# STM32L072xx register map
File version: 1.0
Registers are 32-bit, read-write, reset 0x0 unless marked. A register's access mark holds for its fields unless they carry their own. Offsets are from the block's base; [hi:lo] are bit positions; lines under a group give offsets from that group.

## ADC1 — Analog to Digital Converter
Base 0x40012400
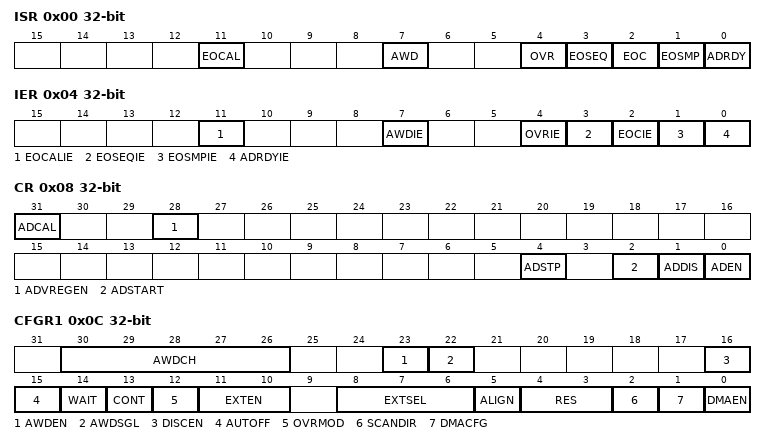
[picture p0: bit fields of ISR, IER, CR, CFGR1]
0x00 ISR — ADC Interrupt and Status register
  [11] EOCAL — End of calibration flag
  [7] AWD — Analog watchdog flag
  [4] OVR — Overrun flag
  [3] EOSEQ — End of Sequence flag
  [2] EOC — End of Conversion
  [1] EOSMP — End of sampling flag
  [0] ADRDY — ADC Ready
0x04 IER — ADC Interrupt Enable register
  [11] EOCALIE — Enf Of Calibration interrupt enable
  [7] AWDIE — Analog Watchdog interrupt enable
  [4] OVRIE — Overrun interrupt enable
  [3] EOSEQIE — End of Sequence of conversion interrupt enable
  [2] EOCIE — End of Conversion interrupt enable
  [1] EOSMPIE — End of sampling interrupt enable
  [0] ADRDYIE — ADC Ready interrupt enable
0x08 CR — ADC Control register
  [31] ADCAL — ADC calibration
  [28] ADVREGEN — ADC Voltage Regulator Enable
  [4] ADSTP — ADC stop of conversion command
  [2] ADSTART — ADC start of conversion
  [1] ADDIS — ADC disable command
  [0] ADEN — ADC enable control
0x0C CFGR1 — ADC Configuration register 1
  [30:26] AWDCH — AWDCH[4:0] bits (Analog watchdog channel select bits)
  [23] AWDEN — Analog watchdog enable on regular channels
  [22] AWDSGL — Enable the watchdog on a single channel or on all channels
  [16] DISCEN — Discontinuous mode on regular channels
    0=DISABLE (ADC group regular sequencer discontinuous mode disable); 1=DISCONT_1RANK (ADC group regular sequencer discontinuous mode enable with sequence interruption every rank)
  [15] AUTOFF — ADC auto power off
  [14] WAIT — ADC wait conversion mode
  [13] CONT — Continuous Conversion
    0=SINGLE (ADC conversions are performed in single mode: one conversion per trigger); 1=CONTINUOUS (ADC conversions are performed in continuous mode: after the first trigger, following conversions launched successively automatically)
  [12] OVRMOD — Overrun mode
    0=PRESERVED (ADC group regular behavior in case of overrun: data preserved); 1=OVERWRITTEN (ADC group regular behavior in case of overrun: data overwritten)
  [11:10] EXTEN — EXTEN[1:0] bits (External Trigger Conversion mode for regular channels)
    1=RISING (ADC group regular conversion trigger polarity set to rising edge); 2=FALLING (ADC group regular conversion trigger polarity set to falling edge); 3=RISINGFALLING (ADC group regular conversion trigger polarity set to both rising and falling edges)
  [8:6] EXTSEL — EXTSEL[2:0] bits (External Event Select for regular group)
  [5] ALIGN — Data Alignment
    0=RIGHT (ADC conversion data alignment: right aligned (alignment on data register LSB bit 0)); 1=LEFT (ADC conversion data alignment: left aligned (alignment on data register MSB bit 15))
  [4:3] RES — RES[1:0] bits (Resolution)
    0=RESOLUTION_12B (ADC resolution 12 bits); 1=RESOLUTION_10B (ADC resolution 10 bits); 2=RESOLUTION_8B (ADC resolution 8 bits); 3=RESOLUTION_6B (ADC resolution 6 bits)
  [2] SCANDIR — Sequence scan direction
    0=FORWARD (ADC group regular sequencer scan direction forward: from lowest channel number to highest channel number (scan of all ranks, ADC conversion of ranks with channels enabled in sequencer). On some other STM32 families, this setting is not available and the default scan direction is forward.); 1=BACKWARD (ADC group regular sequencer scan direction backward: from highest channel number to lowest channel number (scan of all ranks, ADC conversion of ranks with channels enabled in sequencer))
  [1] DMACFG — Direct memory access configuration
  [0] DMAEN — Direct memory access enable
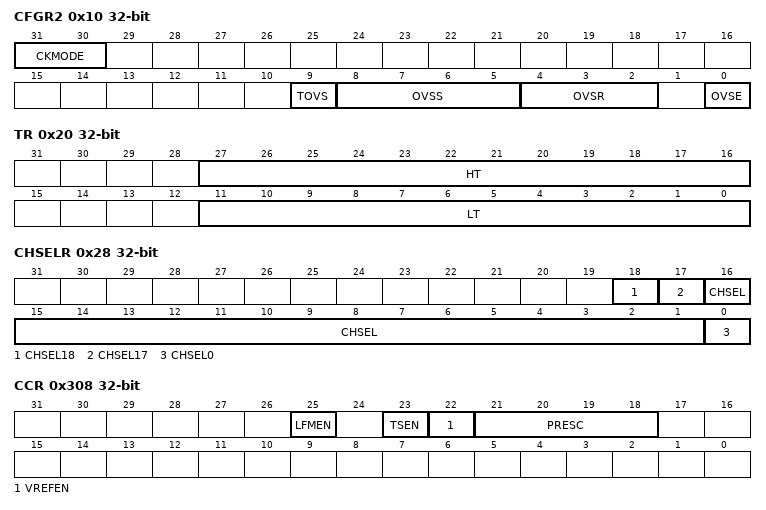
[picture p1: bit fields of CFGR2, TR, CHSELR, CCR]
0x10 CFGR2 — ADC Configuration register 2
  [31:30] CKMODE — CKMODE [1:0] bits (ADC clock mode)
    2=SYNC_PCLK_DIV4 (ADC synchronous clock derived from AHB clock divided by 4); 1=SYNC_PCLK_DIV2 (ADC synchronous clock derived from AHB clock divided by 2); 3=SYNC_PCLK_DIV1 (ADC synchronous clock derived from AHB clock not divided); 0=ASYNC (ADC asynchronous clock. Asynchronous clock prescaler can be configured using function @ref LL_ADC_SetCommonClock().)
  [9] TOVS — Triggered Oversampling
    0=CONT (ADC oversampling discontinuous mode: continuous mode (all conversions of oversampling ratio are done from 1 trigger)); 1=DISCONT (ADC oversampling discontinuous mode: discontinuous mode (each conversion of oversampling ratio needs a trigger))
  [8:5] OVSS — OVSS [3:0] bits (Oversampling shift)
    0=NONE (ADC oversampling no shift (sum of the ADC conversions data is not divided to result as the ADC oversampling conversion data)); 1=RIGHT_1 (ADC oversampling shift of 1 (sum of the ADC conversions data is divided by 2 to result as the ADC oversampling conversion data)); 2=RIGHT_2 (ADC oversampling shift of 2 (sum of the ADC conversions data is divided by 4 to result as the ADC oversampling conversion data)); 3=RIGHT_3 (ADC oversampling shift of 3 (sum of the ADC conversions data is divided by 8 to result as the ADC oversampling conversion data)); 4=RIGHT_4 (ADC oversampling shift of 4 (sum of the ADC conversions data is divided by 16 to result as the ADC oversampling conversion data)); 5=RIGHT_5 (ADC oversampling shift of 5 (sum of the ADC conversions data is divided by 32 to result as the ADC oversampling conversion data)); 6=RIGHT_6 (ADC oversampling shift of 6 (sum of the ADC conversions data is divided by 64 to result as the ADC oversampling conversion data)); 7=RIGHT_7 (ADC oversampling shift of 7 (sum of the ADC conversions data is divided by 128 to result as the ADC oversampling conversion data)); 8=RIGHT_8 (ADC oversampling shift of 8 (sum of the ADC conversions data is divided by 256 to result as the ADC oversampling conversion data))
  [4:2] OVSR — OVSR [2:0] bits (Oversampling ratio)
    0=RATIO_2 (ADC oversampling ratio of 2 (2 ADC conversions are performed, sum of these conversions data is computed to result as the ADC oversampling conversion data (before potential shift)); 1=RATIO_4 (ADC oversampling ratio of 4 (4 ADC conversions are performed, sum of these conversions data is computed to result as the ADC oversampling conversion data (before potential shift)); 2=RATIO_8 (ADC oversampling ratio of 8 (8 ADC conversions are performed, sum of these conversions data is computed to result as the ADC oversampling conversion data (before potential shift)); 3=RATIO_16 (ADC oversampling ratio of 16 (16 ADC conversions are performed, sum of these conversions data is computed to result as the ADC oversampling conversion data (before potential shift)); 4=RATIO_32 (ADC oversampling ratio of 32 (32 ADC conversions are performed, sum of these conversions data is computed to result as the ADC oversampling conversion data (before potential shift)); 5=RATIO_64 (ADC oversampling ratio of 64 (64 ADC conversions are performed, sum of these conversions data is computed to result as the ADC oversampling conversion data (before potential shift)); 6=RATIO_128 (ADC oversampling ratio of 128 (128 ADC conversions are performed, sum of these conversions data is computed to result as the ADC oversampling conversion data (before potential shift)); 7=RATIO_256 (ADC oversampling ratio of 256 (256 ADC conversions are performed, sum of these conversions data is computed to result as the ADC oversampling conversion data (before potential shift))
  [0] OVSE — Oversampler Enable
    0=DISABLE (ADC oversampling disabled.); 1=GRP_REGULAR_CONTINUED (ADC oversampling on conversions of ADC group regular. Literal suffix "continued" is kept for compatibility with other STM32 devices featuring ADC group injected, in this case other oversampling scope parameters are available.)
0x14 SMPR — ADC Sampling time register
  [2:0] SMP — SMPR[2:0] bits (Sampling time selection)
    0=SAMPLINGTIME_1CYCLE_5 (Sampling time 1.5 ADC clock cycle); 1=SAMPLINGTIME_3CYCLES_5 (Sampling time 3.5 ADC clock cycles); 2=SAMPLINGTIME_7CYCLES_5 (Sampling time 7.5 ADC clock cycles); 3=SAMPLINGTIME_12CYCLES_5 (Sampling time 12.5 ADC clock cycles); 4=SAMPLINGTIME_19CYCLES_5 (Sampling time 19.5 ADC clock cycles); 5=SAMPLINGTIME_39CYCLES_5 (Sampling time 39.5 ADC clock cycles); 6=SAMPLINGTIME_79CYCLES_5 (Sampling time 79.5 ADC clock cycles); 7=SAMPLINGTIME_160CYCLES_5 (Sampling time 160.5 ADC clock cycles)
0x20 TR — ADC watchdog threshold register
  [27:16] HT — Analog watchdog high threshold
  [11:0] LT — Analog watchdog low threshold
0x28 CHSELR — ADC channel selection register
  [18] CHSEL18 — Channel 18 selection
  [17] CHSEL17 — Channel 17 selection
  [16:1] CHSEL — ADC group regular sequencer channels
  [0] CHSEL0 — Channel 0 selection
0x40 DR — ADC data register
  [15:0] DATA — Regular data
0xB4 CALFACT — ADC data register
  [6:0] CALFACT — Calibration factor
0x308 CCR
  [25] LFMEN — Low Frequency Mode enable
    0=HIGH (ADC clock mode to high frequency. On STM32L0, ADC clock frequency above 2.8MHz.); 1=LOW (ADC clock mode to low frequency. On STM32L0, ADC clock frequency below 2.8MHz.)
  [23] TSEN — Temperature sensore enable
  [22] VREFEN — Vrefint enable
  [21:18] PRESC — PRESC [3:0] bits (ADC prescaler)
    0=DIV1 (ADC asynchronous clock without prescaler); 1=DIV2 (ADC asynchronous clock with prescaler division by 2. ADC common clock asynchronous prescaler is applied to each ADC instance if the corresponding ADC instance clock is set to clock source asynchronous (refer to function @ref LL_ADC_SetClock() ).); 2=DIV4 (ADC asynchronous clock with prescaler division by 4. ADC common clock asynchronous prescaler is applied to each ADC instance if the corresponding ADC instance clock is set to clock source asynchronous (refer to function @ref LL_ADC_SetClock() ).); 3=DIV6 (ADC asynchronous clock with prescaler division by 6. ADC common clock asynchronous prescaler is applied to each ADC instance if the corresponding ADC instance clock is set to clock source asynchronous (refer to function @ref LL_ADC_SetClock() ).); 4=DIV8 (ADC asynchronous clock with prescaler division by 8. ADC common clock asynchronous prescaler is applied to each ADC instance if the corresponding ADC instance clock is set to clock source asynchronous (refer to function @ref LL_ADC_SetClock() ).); 5=DIV10 (ADC asynchronous clock with prescaler division by 10. ADC common clock asynchronous prescaler is applied to each ADC instance if the corresponding ADC instance clock is set to clock source asynchronous (refer to function @ref LL_ADC_SetClock() ).); 6=DIV12 (ADC asynchronous clock with prescaler division by 12. ADC common clock asynchronous prescaler is applied to each ADC instance if the corresponding ADC instance clock is set to clock source asynchronous (refer to function @ref LL_ADC_SetClock() ).); 7=DIV16 (ADC asynchronous clock with prescaler division by 16. ADC common clock asynchronous prescaler is applied to each ADC instance if the corresponding ADC instance clock is set to clock source asynchronous (refer to function @ref LL_ADC_SetClock() ).); 8=DIV32 (ADC asynchronous clock with prescaler division by 32. ADC common clock asynchronous prescaler is applied to each ADC instance if the corresponding ADC instance clock is set to clock source asynchronous (refer to function @ref LL_ADC_SetClock() ).); 9=DIV64 (ADC asynchronous clock with prescaler division by 64. ADC common clock asynchronous prescaler is applied to each ADC instance if the corresponding ADC instance clock is set to clock source asynchronous (refer to function @ref LL_ADC_SetClock() ).); 10=DIV128 (ADC asynchronous clock with prescaler division by 128. ADC common clock asynchronous prescaler is applied to each ADC instance if the corresponding ADC instance clock is set to clock source asynchronous (refer to function @ref LL_ADC_SetClock() ).); 11=DIV256 (ADC asynchronous clock with prescaler division by 256. ADC common clock asynchronous prescaler is applied to each ADC instance if the corresponding ADC instance clock is set to clock source asynchronous (refer to function @ref LL_ADC_SetClock() ).)
